VERSION ""

NS_ :

BS_:

BU_:

BO_ [CAN ID] [MessageName]: [NumBytes] [Sender]
 SG_ [SignalName] : [StartBit]|[Length]@[ByteOrder][ValueType] ([Scale],[Offset]) [[Min]|[Max]] "[Unit]" [Receivers]

++++++++++ EXAMPLES ++++++++++++

VERSION ""

NS_ :

BS_:

BU_:

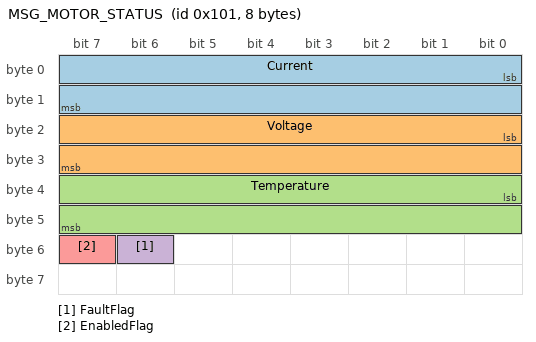
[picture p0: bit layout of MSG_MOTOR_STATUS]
BO_ 257 MSG_MOTOR_STATUS: 8 Motor_Controller
 SG_ Current : 0|16@1- (0.01,0) [-327.68|327.67] "A" Vector__XXX
 SG_ Voltage : 16|16@1- (0.01,0) [0|55] "V" Vector__XXX
 SG_ Temperature : 32|16@1+ (0.1,0) [0|150] "degC" Vector__XXX
 SG_ FaultFlag : 54|1@1+ (1,0) [0|1] "" Vector__XXX
 SG_ EnabledFlag : 55|1@1+ (1,0) [0|1] "" Vector__XXX

BO_ 258 MSG_MOTOR_REQUEST: 4 Brain
 SG_ RequestID: 0|1@1+ (1,0) [0|1] "" Vector__XXX

BO_259 MSG_MOTOR_TELEMETRY: 8 Motor_Controller
 SG_ Position : 48|16@1- (1,0) [-360|360] "deg" Vector__XXX *** Output: degree of motor itself. Needs to be divided by gear ratio of gear box for real output.

- no PID anything!
- no having to request stuff (just spit everything out!) ---------------------------------------------

**Don't send RPM. Have a function get "Position" and convert to RPM
voltage, current, position, speed, some temperatures, some fault codes
the motor drivers will send 4 temperatures each at 16bit, bus current & voltage at 16bit. these values should be scaled down a lot since we dont need the resolution
this will be at 2hz for now
they will also send positional data at 14bit and 1000hz
the jetson will send positional data at lets assume 14bit for now at 100hz
